# ATmega406 register map
Vendor: Atmel; File version: 1.0
CPU: other r0p0, little endian, no MPU, no FPU, 4 interrupt priority bits
Registers are 8-bit, read-write, reset 0x0 unless marked. A register's access mark holds for its fields unless they carry their own. Offsets are from the block's base; lines under a group give offsets from that group; [hi:lo] are bit positions; {n}, {i} and the like mark numbered series; 'fields as' and 'values as' point back to an identical list; <NAME> marks a mode.

## Memory map
0x00800000 FUSE size 0x2 — Fuses
0x00800000 LOCKBIT size 0x1 — Lockbits
0x00800020 PORTA size 0x3 — I/O Port
0x00800023 PORTB size 0x3 — I/O Port
0x00800028 PORTC size 0x1 — I/O Port
0x00800029 PORTD size 0x3 — I/O Port
0x00800035 TC0 blocks up to offset 0x3A — Timer/Counter, 8-bit
0x00800036 TC1 blocks up to offset 0x54 — Timer/Counter, 16-bit
0x0080003B EXINT blocks up to offset 0x32 — External Interrupts
0x0080003E CPU blocks up to offset 0x83 — CPU Registers
0x0080003F EEPROM size 0x4
0x00800057 BOOT_LOAD size 0x1 — Bootloader
0x00800060 WDT size 0x1 — Watchdog Timer
0x00800062 WAKEUP_TIMER size 0x1
0x00800078 ADC blocks up to offset 0x5 — Analog-to-Digital Converter
0x008000B8 TWI size 0x7 — Two Wire Serial Interface
0x008000D0 BANDGAP size 0x2
0x008000E0 COULOMB_COUNTER size 0xA
0x008000F0 FET size 0x1 — FET Control
0x008000F1 CELL_BALANCING size 0x1
0x008000F2 BATTERY_PROTECTION size 0x7

## Interrupts
0 RESET (CPU) — External Pin, Power-on Reset, Brown-out Reset and Watchdog Reset
1 BPINT (CPU) — Battery Protection Interrupt
2 INT0 (CPU) — External Interrupt Request 0
3 INT1 (CPU) — External Interrupt Request 1
4 INT2 (CPU) — External Interrupt Request 2
5 INT3 (CPU) — External Interrupt Request 3
6 PCINT0 (CPU) — Pin Change Interrupt 0
7 PCINT1 (CPU) — Pin Change Interrupt 1
8 WDT (CPU) — Watchdog Timeout Interrupt
9 WAKE_UP (CPU) — Wakeup timer overflow
10 TIM1_COMP (CPU) — Timer/Counter 1 Compare Match
11 TIM1_OVF (CPU) — Timer/Counter 1 Overflow
12 TIM0_COMPA (CPU) — Timer/Counter0 Compare A Match
13 TIM0_COMPB (CPU) — Timer/Counter0 Compare B Match
14 TIM0_OVF (CPU) — Timer/Counter0 Overflow
15 TWI_BUS_CD (CPU) — Two-Wire Bus Connect/Disconnect
16 TWI (CPU) — Two-Wire Serial Interface
17 VADC (CPU) — Voltage ADC Conversion Complete
18 CCADC_CONV (CPU) — Coulomb Counter ADC Conversion Complete
19 CCADC_REG_CUR (CPU) — Coloumb Counter ADC Regular Current
20 CCADC_ACC (CPU) — Coloumb Counter ADC Accumulator
21 EE_READY (CPU) — EEPROM Ready
22 SPM_READY (CPU) — Store Program Memory Ready

## ADC — Analog-to-Digital Converter
Base 0x00800078
0x00 VADC 16-bit (reset mask 0xFF) — VADC Data Register Bytes
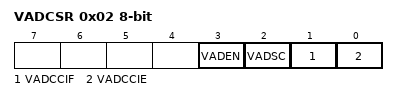
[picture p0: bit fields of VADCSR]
0x02 VADCSR — The VADC Control and Status register (read-only for debugger)
  [3] VADEN — VADC Enable
  [2] VADSC — VADC Satrt Conversion
  [1] VADCCIF — VADC Conversion Complete Interrupt Flag
  [0] VADCCIE — VADC Conversion Complete Interrupt Enable
0x04 VADMUX — The VADC multiplexer Selection Register
  [3:0] VADMUX — Analog Channel and Gain Selection Bits

## BANDGAP
Base 0x008000D0
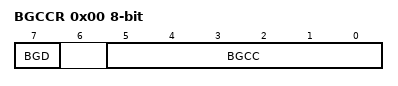
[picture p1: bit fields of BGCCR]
0x00 BGCCR — Bandgap Calibration Register
  [7] BGD — Setting the BGD bit to one will disable the bandgap voltage reference. This bit must be cleared before enabling CC-ADC or V-ADC, and must remain unset while either ADC is enabled.
  [5:0] BGCC — BG Calibration of PTAT Current Bits
0x01 BGCRR — Bandgap Calibration of Resistor Ladder

## BATTERY_PROTECTION
Base 0x008000F2
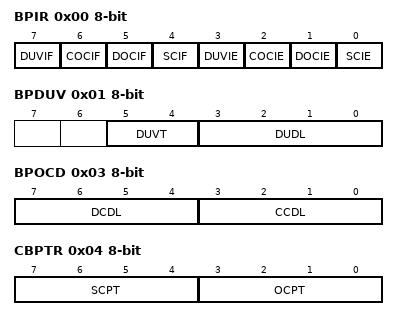
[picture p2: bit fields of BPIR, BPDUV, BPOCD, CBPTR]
0x00 BPIR — Battery Protection Interrupt Register (read-only for debugger)
  [7] DUVIF — Deep Under-voltage Early Warning Interrupt Flag
  [6] COCIF — Charge Over-current Protection Activated Interrupt Flag
  [5] DOCIF
  [4] SCIF
  [3] DUVIE — Deep Under-voltage Early Warning Interrupt Enable
  [2] COCIE
  [1] DOCIE
  [0] SCIE
0x01 BPDUV — Battery Protection Deep Under Voltage Register
  [5:4] DUVT
    0=750MS; 1=1000MS; 2=1250MS; 3=1500MS
  [3:0] DUDL
    0=4_71V; 1=5_03V; 2=5_34V; 3=5_66V; 4=5_97V; 5=6_29V; 6=6_60V; 7=6_91V; 8=7_23V; 9=7_54V; 10=7_86V; 11=8_17V; 12=8_49V; 13=8_80V; 14=9_11V; 15=9_43V
0x02 BPSCD — Battery Protection Short-Circuit Detection Level Register
  [3:0] SCDL
    0=0_100V; 1=0_110V; 2=0_120V; 3=0_130V; 4=0_140V; 5=0_160V; 6=0_180V; 7=0_200V; 8=0_220V; 9=0_240V; 10=0_260V; 11=0_280V; 12=0_320V; 13=0_360V; 14=0_400V; 15=0_440V
0x03 BPOCD — Battery Protection OverCurrent Detection Level Register
  [7:4] DCDL
    0=0_050V; 1=0_055V; 2=0_060V; 3=0_065V; 4=0_070V; 5=0_080V; 6=0_090V; 7=0_100V; 8=0_110V; 9=0_120V; 10=0_130V; 11=0_140V; 12=0_160V; 13=0_180V; 14=0_200V; 15=0_220V
  [3:0] CCDL
    values as DCDL
0x04 CBPTR — Current Battery Protection Timing Register
  [7:4] SCPT
    0=61_US; 1=122_US; 2=183_US; 3=244_US; 4=305_US; 5=366_US; 6=427_US; 7=488_US; 8=610_US; 9=732_US; 10=854_US; 11=976_US; 12=1098_US; 13=1220_US; 14=1342_US; 15=1464_US
  [3:0] OCPT
    0=1_MS; 1=2_MS; 2=4_MS; 3=6_MS; 4=8_MS; 5=10_MS; 6=12_MS; 7=14_MS; 8=16_MS; 9=18_MS; 10=20_MS; 11=22_MS; 12=24_MS; 13=26_MS; 14=28_MS; 15=30_MS
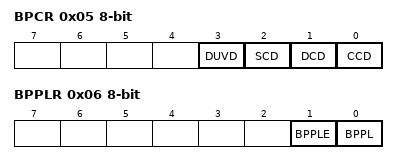
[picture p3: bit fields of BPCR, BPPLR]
0x05 BPCR — Battery Protection Control Register
  [3] DUVD, [2] SCD, [1] DCD, [0] CCD
0x06 BPPLR — Battery Protection Parameter Lock Register (read-only for debugger)
  [1] BPPLE — Battery Protection Parameter Lock Enable
  [0] BPPL — Battery Protection Parameter Lock
